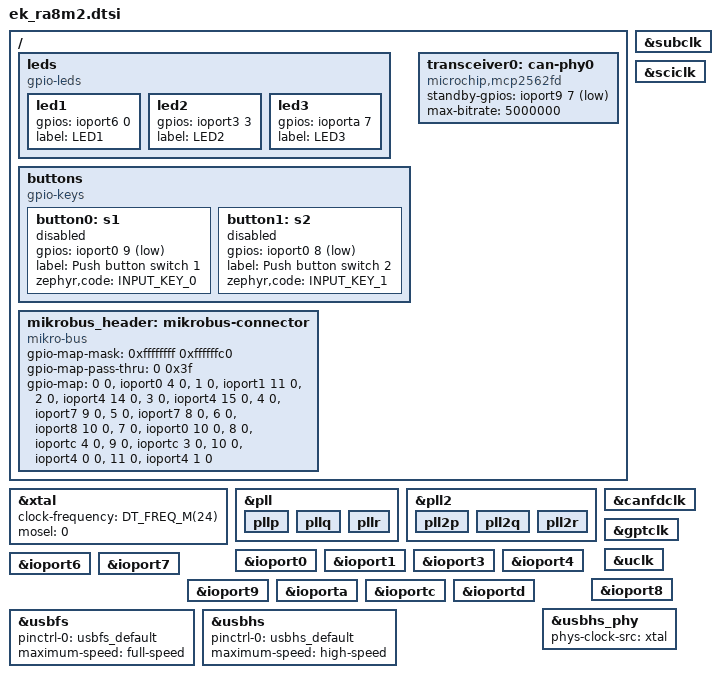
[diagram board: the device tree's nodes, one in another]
/*
 * Copyright (c) 2025 Renesas Electronics Corporation
 * SPDX-License-Identifier: Apache-2.0
 */

#include <dt-bindings/gpio/gpio.h>
#include <dt-bindings/input/input-event-codes.h>
#include "ek_ra8m2-pinctrl.dtsi"

/ {
	leds {
		compatible = "gpio-leds";

		led1: led1 {
			gpios = <&ioport6 0 GPIO_ACTIVE_HIGH>;
			label = "LED1";
		};

		led2: led2 {
			gpios = <&ioport3 3 GPIO_ACTIVE_HIGH>;
			label = "LED2";
		};

		led3: led3 {
			gpios = <&ioporta 7 GPIO_ACTIVE_HIGH>;
			label = "LED3";
		};
	};

	buttons {
		compatible = "gpio-keys";

		button0: s1 {
			gpios = <&ioport0 9 (GPIO_PULL_UP | GPIO_ACTIVE_LOW)>;
			label = "Push button switch 1";
			zephyr,code = <INPUT_KEY_0>;
			status = "disabled";
		};

		button1: s2 {
			gpios = <&ioport0 8 (GPIO_PULL_UP | GPIO_ACTIVE_LOW)>;
			label = "Push button switch 2";
			zephyr,code = <INPUT_KEY_1>;
			status = "disabled";
		};
	};

	mikrobus_header: mikrobus-connector {
		compatible = "mikro-bus";
		#gpio-cells = <2>;
		gpio-map-mask = <0xffffffff 0xffffffc0>;
		gpio-map-pass-thru = <0 0x3f>;
		gpio-map = <0 0 &ioport0 4 0>,	/* AN  */
			   <1 0 &ioport1 11 0>,	/* RST */
			   <2 0 &ioport4 14 0>,	/* CS   */
			   <3 0 &ioport4 15 0>,	/* SCK  */
			   <4 0 &ioport7 9 0>,	/* MISO */
			   <5 0 &ioport7 8 0>,	/* MOSI */
			   /* +3.3V */
			   /* GND */
			   <6 0 &ioport8 10 0>,	/* PWM  */
			   <7 0 &ioport0 10 0>,	/* INT  */
			   <8 0 &ioportc 4 0>,	/* RX   */
			   <9 0 &ioportc 3 0>,	/* TX   */
			   <10 0 &ioport4 0 0>, /* SCL  */
			   <11 0 &ioport4 1 0>; /* SDA  */
		/* +5V */
		/* GND */
	};

	transceiver0: can-phy0 {
		compatible = "microchip,mcp2562fd", "can-transceiver-gpio";
		standby-gpios = <&ioport9 7 GPIO_ACTIVE_LOW>;
		max-bitrate = <5000000>;
		#phy-cells = <0>;
	};
};

&xtal {
	clock-frequency = <DT_FREQ_M(24)>;
	mosel = <0>;
	#clock-cells = <0>;
	status = "okay";
};

&subclk {
	status = "okay";
};

&pll {
	status = "okay";

	pllp: pllp {
		status = "okay";
	};

	pllq: pllq {
		status = "okay";
	};

	pllr: pllr {
		status = "okay";
	};
};

&pll2 {
	status = "okay";

	pll2p {
		status = "okay";
	};

	pll2q {
		status = "okay";
	};

	pll2r {
		status = "okay";
	};
};

&sciclk {
	status = "okay";
};

&canfdclk {
	status = "okay";
};

&gptclk {
	status = "okay";
};

&uclk {
	status = "okay";
};

&ioport0 {
	status = "okay";
};

&ioport1 {
	status = "okay";
};

&ioport3 {
	status = "okay";
};

&ioport4 {
	status = "okay";
};

&ioport6 {
	status = "okay";
};

&ioport7 {
	status = "okay";
};

&ioport8 {
	status = "okay";
};

&ioport9 {
	status = "okay";
};

&ioporta {
	status = "okay";
};

&ioportc {
	status = "okay";
};

&ioportd {
	status = "okay";
};

&usbfs {
	pinctrl-0 = <&usbfs_default>;
	pinctrl-names = "default";
	maximum-speed = "full-speed";
};

&usbhs {
	pinctrl-0 = <&usbhs_default>;
	pinctrl-names = "default";
	maximum-speed = "high-speed";
};

&usbhs_phy {
	phys-clock-src = "xtal";
};
